# R7FA0E107 register map
Vendor: Renesas Electronics Corporation; Series: RA0; File version: 1.10.00
CPU: CM23 r1p0, little endian, no MPU, no FPU, VTOR, 2 interrupt priority bits, 64 interrupts
Registers are 16-bit, read-write, reset 0x0 unless marked. A register's access mark holds for its fields unless they carry their own. Offsets are from the block's base; [hi:lo] are bit positions; {n}, {i} and the like mark numbered series.

## PORGA — Product Organize
Base 0x400A1000
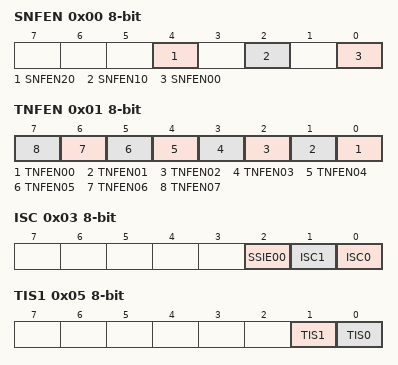
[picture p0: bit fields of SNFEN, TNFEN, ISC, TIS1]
0x00 SNFEN 8-bit — SAU Noise Filter Enable Register
  [4] SNFEN20 — Use of Noise Filter of RXD2 Pin
  [2] SNFEN10 — Use of Noise Filter of RXD1 Pin
  [0] SNFEN00 — Use of Noise Filter of RXD0 Pin
0x01 TNFEN 8-bit — TAU Noise Filter Enable Register
  [n] TNFEN{n:02} (n=0..7) — Enabling or Disabling Use of the Noise Filter for the TI{n:02} Pin
0x03 ISC 8-bit — Input Switch Control Register
  [2] SSIE00 — Setting of the SSI00 Input of Channel 0 in the Communications Through SPI00 in the Slave Mode
  [1] ISC1 — Switching Channel 7 Input of Timer Array Unit
  [0] ISC0 — Switching External Interrupt (IRQ0) Input
0x04 TIS0 8-bit — Timer Input Select Register 0
  [2:0] TIS — Selection of Timer Input Used with Channel 5
0x05 TIS1 8-bit — Timer Input Select Register 1
  [1] TIS1 — Selection of Timer Input Used with Channel 1
  [0] TIS0 — Selection of Timer Input Used with Channel 0
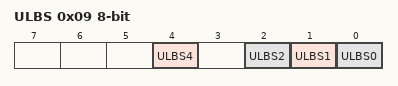
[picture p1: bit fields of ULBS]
0x09 ULBS 8-bit — UART Loopback Select Register
  [4] ULBS4 — Selection of the UARTA Loopback Function
  [2] ULBS2 — Selection of the UART2 Loopback Function
  [1] ULBS1 — Selection of the UART1 Loopback Function
  [0] ULBS0 — Selection of the UART0 Loopback Function

## ADC_D — A/D Converter
Base 0x400A1800
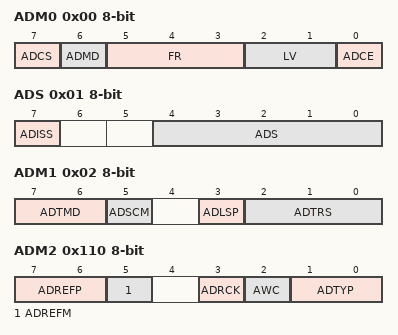
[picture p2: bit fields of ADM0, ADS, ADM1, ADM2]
0x00 ADM0 8-bit — A/D Converter Mode Register 0
  [7] ADCS — A/D conversion operation control
  [6] ADMD — Specification of the A/D conversion channel selection mode
  [5:3] FR — Select Conversion Clock (fAD)
  [2:1] LV — Select Operation voltage mode
  [0] ADCE — A/D voltage comparator operation control
0x01 ADS 8-bit — Analog Input Channel Specification Register
  [7] ADISS — Select Internal or External of Analog Input (See to )
  [4:0] ADS — Selection of the Analog Input Channel (See to )
0x02 ADM1 8-bit — A/D Converter Mode Register 1
  [7:6] ADTMD — Selection of the A/D Conversion Trigger Mode
  [5] ADSCM — Specification of the A/D Conversion Mode
  [3] ADLSP — PCLKB Input Frequency Setting
  [2:0] ADTRS — Selection of the Hardware Trigger Signal
0x06 ADCR ro — 12-bit or 10-bit A/D Conversion Result Register
0x07 ADCRH 8-bit ro — 8-bit A/D Conversion Result Register
0x110 ADM2 8-bit — A/D Converter Mode Register 2
  [7:6] ADREFP, [5] ADREFM, [3] ADRCK, [2] AWC, [1:0] ADTYP
0x111 ADUL 8-bit reset 0xFF — Conversion Result Comparison Upper Limit Setting Register
0x112 ADLL 8-bit — Conversion Result Comparison Lower Limit Setting Register
0x113 ADTES 8-bit — A/D Test Register
  [1:0] ADTES — Selection of A/D Conversion Target for Testing
{0x120+2i} ADCR{i} ro (i=0..3) — 12-bit or 10-bit A/D Conversion Result Register {i}
{0x121+2i} ADCR{i}H 8-bit ro (i=0..3) — 8-bit A/D Conversion Result Register {i}

## RTC_C — Realtime Clock
Base 0x400A2C00
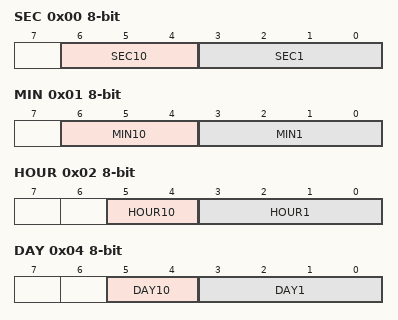
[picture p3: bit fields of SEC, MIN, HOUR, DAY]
0x00 SEC 8-bit (reset mask 0x80) — Second Count Register
  [6:4] SEC10 — 10-second count
  [3:0] SEC1 — 1-second count
0x01 MIN 8-bit (reset mask 0x80) — Minute Count Register
  [6:4] MIN10 — 10- minute count
  [3:0] MIN1 — 1-minute count
0x02 HOUR 8-bit (reset mask 0xC0) — Hour Count Register
  [5:4] HOUR10 — 10-hour count
  [3:0] HOUR1 — 1-hour count
0x03 WEEK 8-bit (reset mask 0xF8) — Day,of,Week Count Register
  [2:0] WEEK — Day,of,Week Counting
0x04 DAY 8-bit (reset mask 0xC0) — Day Count Register
  [5:4] DAY10 — 10-day count
  [3:0] DAY1 — 1-day count
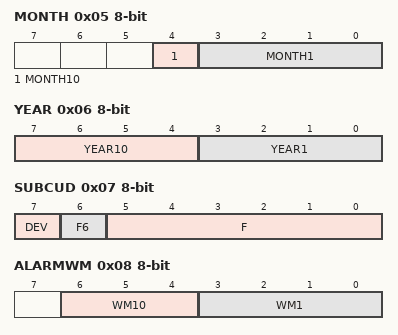
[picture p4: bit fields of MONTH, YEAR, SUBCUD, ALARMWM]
0x05 MONTH 8-bit (reset mask 0xE0) — Month Count Register
  [4] MONTH10 — 10-month count
  [3:0] MONTH1 — 1-month count
0x06 YEAR 8-bit reset not defined — Year Count Register
  [7:4] YEAR10 — 10-year count
  [3:0] YEAR1 — 1-year count
0x07 SUBCUD 8-bit — Time Error Correction Register
  [7] DEV — Setting of time error correction timing
  [6] F6 — Setting of time error correction value
  [5:0] F — Adjustment Value
0x08 ALARMWM 8-bit (reset mask 0x80) — Alarm Minute Register
  [6:4] WM10 — 10-digit minute setting
  [3:0] WM1 — 1-digit minute setting
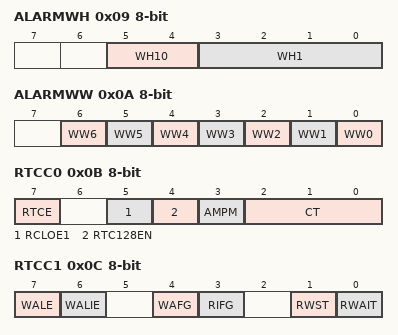
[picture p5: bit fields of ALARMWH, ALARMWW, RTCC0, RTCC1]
0x09 ALARMWH 8-bit (reset mask 0xC0) — Alarm Hour Register
  [5:4] WH10 — 10-digit hour setting
  [3:0] WH1 — 1-digit hour setting
0x0A ALARMWW 8-bit (reset mask 0x80) — Alarm Day,of,Week Register
  [6] WW6 — Alarm enabled setting "Saturday"
  [5] WW5 — Alarm enabled setting "Friday"
  [4] WW4 — Alarm enabled setting "Thursday"
  [3] WW3 — Alarm enabled setting "Wednesday"
  [2] WW2 — Alarm enabled setting "Tuesday"
  [1] WW1 — Alarm enabled setting "Monday"
  [0] WW0 — Alarm enabled setting "Sunday"
0x0B RTCC0 8-bit — Realtime Clock Control Register 0
  [7] RTCE — Realtime clock operation control
  [5] RCLOE1 — RTCOUT pin output control
  [4] RTC128EN — Selection of the operating clock for the realtime clock (RTCCLK)
  [3] AMPM — Selection of 12- or 24-hour system
  [2:0] CT — Fixed,cycle interrupt (RTC_ALM_OR_PRD) selection
0x0C RTCC1 8-bit — Realtime Clock Control Register 1
  [7] WALE — Alarm operation control
  [6] WALIE — Control of alarm interrupt (RTC_ALM_OR_PRD)
  [4] WAFG — Alarm detection status flag
  [3] RIFG — Fixed,cycle interrupt status flag
  [1] RWST ro — Wait status flag of realtime clock
  [0] RWAIT — Wait control of realtime clock
